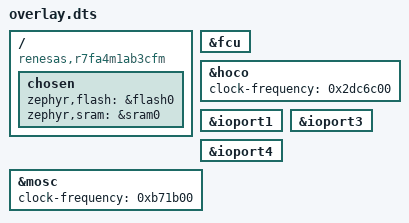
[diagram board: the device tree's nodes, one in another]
/ {
	compatible = "renesas,r7fa4m1ab3cfm";
	chosen {
		zephyr,flash = &flash0;
		zephyr,sram = &sram0;
	};
};
&fcu{
	status = "okay";
};
&hoco{
	clock-frequency = < 0x2dc6c00 >;
};
&ioport1{
	status = "okay";
};
&ioport3{
	status = "okay";
};
&ioport4{
	status = "okay";
};
&mosc{
	clock-frequency = < 0xb71b00 >;
	status = "okay";
};
